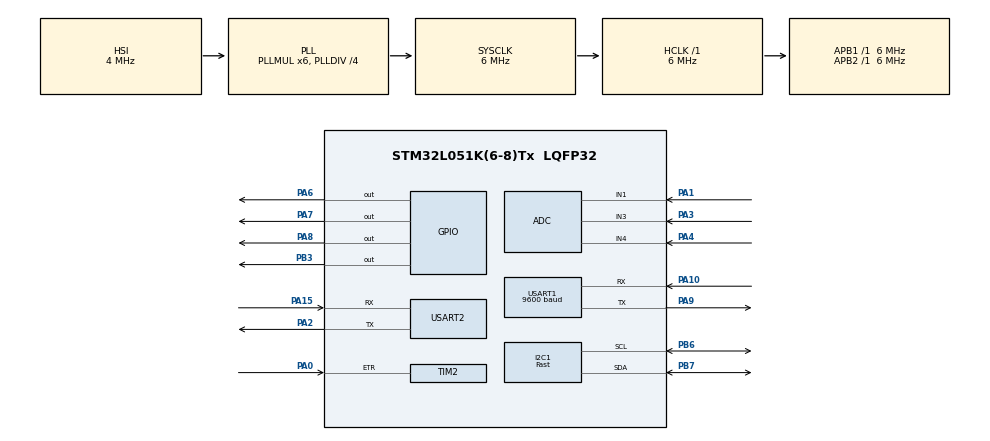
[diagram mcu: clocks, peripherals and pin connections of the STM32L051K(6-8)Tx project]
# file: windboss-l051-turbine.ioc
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ADC.ClockPrescaler=ADC_CLOCK_ASYNC_DIV1
ADC.ContinuousConvMode=ENABLE
ADC.DMAContinuousRequests=ENABLE
Dma.ADC.0.Direction=DMA_PERIPH_TO_MEMORY
Dma.ADC.0.Instance=DMA1_Channel1
Dma.ADC.0.MemDataAlignment=DMA_MDATAALIGN_HALFWORD
Dma.ADC.0.MemInc=DMA_MINC_ENABLE
Dma.ADC.0.Mode=DMA_NORMAL
Dma.ADC.0.PeriphDataAlignment=DMA_PDATAALIGN_HALFWORD
Dma.ADC.0.PeriphInc=DMA_PINC_DISABLE
Dma.ADC.0.Priority=DMA_PRIORITY_VERY_HIGH
Dma.Request0=ADC
I2C1.I2C_Speed_Mode=I2C_Fast
I2C1.Timing=0x00000107
Mcu.Family=STM32L0
Mcu.Name=STM32L051K(6-8)Tx
Mcu.Package=LQFP32
NVIC.DMA1_Channel1_IRQn=true\:0\:0\:false\:false\:true\:false\:true\:true
NVIC.USART1_IRQn=true\:0\:0\:false\:false\:true\:true\:true\:true
PA0.GPIO_Speed=GPIO_SPEED_FREQ_VERY_HIGH
PA0.Signal=S_TIM2_ETR
PA1.Mode=IN1
PA1.Signal=ADC_IN1
PA10.GPIO_PuPd=GPIO_PULLUP
PA10.Mode=Asynchronous
PA10.Signal=USART1_RX
PA13.Mode=Serial_Wire
PA13.Signal=SYS_SWDIO
PA14.Mode=Serial_Wire
PA14.Signal=SYS_SWCLK
PA15.GPIO_PuPd=GPIO_PULLUP
PA15.Mode=Asynchronous
PA15.Signal=USART2_RX
PA2.GPIO_PuPd=GPIO_PULLUP
PA2.Mode=Asynchronous
PA2.Signal=USART2_TX
PA3.Mode=IN3
PA3.Signal=ADC_IN3
PA4.Mode=IN4
PA4.Signal=ADC_IN4
PA5.Signal=S_TIM2_CH1
PA6.GPIO_Speed=GPIO_SPEED_FREQ_HIGH
PA6.Signal=GPIO_Output
PA7.GPIO_Speed=GPIO_SPEED_FREQ_HIGH
PA7.Signal=GPIO_Output
PA8.GPIO_Speed=GPIO_SPEED_FREQ_HIGH
PA8.Signal=GPIO_Output
PA9.GPIO_PuPd=GPIO_PULLUP
PA9.Mode=Asynchronous
PA9.Signal=USART1_TX
PB3.GPIO_PuPd=GPIO_PULLUP
PB3.GPIO_Speed=GPIO_SPEED_FREQ_VERY_HIGH
PB3.PinState=GPIO_PIN_SET
PB3.Signal=GPIO_Output
PB6.GPIO_FM6=I2C_FASTMODEPLUS_PB6
PB6.GPIO_Pu=GPIO_NOPULL
PB6.Mode=I2C
PB6.Signal=I2C1_SCL
PB7.GPIO_FM7=I2C_FASTMODEPLUS_PB7
PB7.GPIO_Pu=GPIO_NOPULL
PB7.Mode=I2C
PB7.Signal=I2C1_SDA
ProjectManager.HeapSize=0x200
ProjectManager.StackSize=0x400
ProjectManager.TargetToolchain=STM32CubeIDE
RCC.ADCFreq_Value=4000000
RCC.AHBFreq_Value=6000000
RCC.APB1Freq_Value=6000000
RCC.APB1TimFreq_Value=6000000
RCC.APB2Freq_Value=6000000
RCC.APB2TimFreq_Value=6000000
RCC.HCLKFreq_Value=6000000
RCC.HSI16_VALUE=16000000
RCC.HSIRCDiv=4
RCC.HSI_VALUE=4000000
RCC.LSE_VALUE=32768
RCC.LptimClockSelection=RCC_LPTIM1CLKSOURCE_HSI
RCC.MSI_VALUE=2097000
RCC.PLLDIV=RCC_PLLDIV_4
RCC.PLLMUL=RCC_PLLMUL_6
RCC.SYSCLKFreq_VALUE=6000000
RCC.SYSCLKSource=RCC_SYSCLKSOURCE_PLLCLK
RCC.Usart1ClockSelection=RCC_USART1CLKSOURCE_SYSCLK
RCC.Usart2ClockSelection=RCC_USART2CLKSOURCE_SYSCLK
RCC.VCOOutputFreq_Value=24000000
SH.S_TIM2_CH1.0=TIM2_CH1
SH.S_TIM2_ETR.0=TIM2_ETR,ClockSourceETR_Mode2
USART1.BaudRate=9600
USART1.DMADisableonRxErrorParam=ADVFEATURE_DMA_DISABLEONRXERROR
USART1.OneBitSampling=UART_ONE_BIT_SAMPLE_DISABLE
USART1.OverSampling=UART_OVERSAMPLING_16
USART1.OverrunDisableParam=ADVFEATURE_OVERRUN_DISABLE
USART1.VirtualMode-Asynchronous=VM_ASYNC
USART2.DMADisableonRxErrorParam=ADVFEATURE_DMA_DISABLEONRXERROR
USART2.OverrunDisableParam=ADVFEATURE_OVERRUN_DISABLE
USART2.VirtualMode-Asynchronous=VM_ASYNC
board=custom

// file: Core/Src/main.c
/* USER CODE BEGIN Header */
/**
  ******************************************************************************
  * @file           : main.c
  * @brief          : Main program body
  ******************************************************************************
  * @attention
  *
  * Copyright (c) 2024 STMicroelectronics.
  * All rights reserved.
  *
  * This software is licensed under terms that can be found in the LICENSE file
  * in the root directory of this software component.
  * If no LICENSE file comes with this software, it is provided AS-IS.
  *
  ******************************************************************************
  */
/* USER CODE END Header */
#include "main.h"

/* USER CODE BEGIN Includes */
#include "tasks.h"
/* USER CODE END Includes */

ADC_HandleTypeDef hadc;
DMA_HandleTypeDef hdma_adc;

I2C_HandleTypeDef hi2c1;

TIM_HandleTypeDef htim2;

UART_HandleTypeDef huart1;
UART_HandleTypeDef huart2;

void SystemClock_Config(void);
static void MX_GPIO_Init(void);
static void MX_DMA_Init(void);
static void MX_ADC_Init(void);
static void MX_I2C1_Init(void);
static void MX_USART1_UART_Init(void);
static void MX_USART2_UART_Init(void);
static void MX_TIM2_Init(void);

int main(void)
{

  /* MCU Configuration--------------------------------------------------------*/

  /* Reset of all peripherals, Initializes the Flash interface and the Systick. */
  HAL_Init();

  /* Configure the system clock */
  SystemClock_Config();

  /* Initialize all configured peripherals */
  MX_GPIO_Init();
  MX_DMA_Init();
  MX_ADC_Init();
  MX_I2C1_Init();
  MX_USART1_UART_Init();
  MX_USART2_UART_Init();
  MX_TIM2_Init();
  /* USER CODE BEGIN 2 */
  tasksInit();
  /* USER CODE END 2 */

  /* Infinite loop */
  while (1)
  {

    /* USER CODE BEGIN 3 */
	tasksLoop();
  }
  /* USER CODE END 3 */
}

void SystemClock_Config(void)
{
  RCC_OscInitTypeDef RCC_OscInitStruct = {0};
  RCC_ClkInitTypeDef RCC_ClkInitStruct = {0};
  RCC_PeriphCLKInitTypeDef PeriphClkInit = {0};

  /** Configure the main internal regulator output voltage
  */
  __HAL_PWR_VOLTAGESCALING_CONFIG(PWR_REGULATOR_VOLTAGE_SCALE1);

  /** Initializes the RCC Oscillators according to the specified parameters
  * in the RCC_OscInitTypeDef structure.
  */
  RCC_OscInitStruct.OscillatorType = RCC_OSCILLATORTYPE_HSI;
  RCC_OscInitStruct.HSIState = RCC_HSI_DIV4;
  RCC_OscInitStruct.HSICalibrationValue = RCC_HSICALIBRATION_DEFAULT;
  RCC_OscInitStruct.PLL.PLLState = RCC_PLL_ON;
  RCC_OscInitStruct.PLL.PLLSource = RCC_PLLSOURCE_HSI;
  RCC_OscInitStruct.PLL.PLLMUL = RCC_PLLMUL_6;
  RCC_OscInitStruct.PLL.PLLDIV = RCC_PLLDIV_4;
  if (HAL_RCC_OscConfig(&RCC_OscInitStruct) != HAL_OK)
  {
    Error_Handler();
  }

  /** Initializes the CPU, AHB and APB buses clocks
  */
  RCC_ClkInitStruct.ClockType = RCC_CLOCKTYPE_HCLK|RCC_CLOCKTYPE_SYSCLK
                              |RCC_CLOCKTYPE_PCLK1|RCC_CLOCKTYPE_PCLK2;
  RCC_ClkInitStruct.SYSCLKSource = RCC_SYSCLKSOURCE_PLLCLK;
  RCC_ClkInitStruct.AHBCLKDivider = RCC_SYSCLK_DIV1;
  RCC_ClkInitStruct.APB1CLKDivider = RCC_HCLK_DIV1;
  RCC_ClkInitStruct.APB2CLKDivider = RCC_HCLK_DIV1;

  if (HAL_RCC_ClockConfig(&RCC_ClkInitStruct, FLASH_LATENCY_0) != HAL_OK)
  {
    Error_Handler();
  }
  PeriphClkInit.PeriphClockSelection = RCC_PERIPHCLK_USART1|RCC_PERIPHCLK_USART2
                              |RCC_PERIPHCLK_I2C1;
  PeriphClkInit.Usart1ClockSelection = RCC_USART1CLKSOURCE_SYSCLK;
  PeriphClkInit.Usart2ClockSelection = RCC_USART2CLKSOURCE_SYSCLK;
  PeriphClkInit.I2c1ClockSelection = RCC_I2C1CLKSOURCE_PCLK1;
  if (HAL_RCCEx_PeriphCLKConfig(&PeriphClkInit) != HAL_OK)
  {
    Error_Handler();
  }
}

static void MX_ADC_Init(void)
{

  ADC_ChannelConfTypeDef sConfig = {0};

  /** Configure the global features of the ADC (Clock, Resolution, Data Alignment and number of conversion)
  */
  hadc.Instance = ADC1;
  hadc.Init.OversamplingMode = DISABLE;
  hadc.Init.ClockPrescaler = ADC_CLOCK_ASYNC_DIV1;
  hadc.Init.Resolution = ADC_RESOLUTION_12B;
  hadc.Init.SamplingTime = ADC_SAMPLETIME_1CYCLE_5;
  hadc.Init.ScanConvMode = ADC_SCAN_DIRECTION_FORWARD;
  hadc.Init.DataAlign = ADC_DATAALIGN_RIGHT;
  hadc.Init.ContinuousConvMode = ENABLE;
  hadc.Init.DiscontinuousConvMode = DISABLE;
  hadc.Init.ExternalTrigConvEdge = ADC_EXTERNALTRIGCONVEDGE_NONE;
  hadc.Init.ExternalTrigConv = ADC_SOFTWARE_START;
  hadc.Init.DMAContinuousRequests = ENABLE;
  hadc.Init.EOCSelection = ADC_EOC_SINGLE_CONV;
  hadc.Init.Overrun = ADC_OVR_DATA_PRESERVED;
  hadc.Init.LowPowerAutoWait = DISABLE;
  hadc.Init.LowPowerFrequencyMode = DISABLE;
  hadc.Init.LowPowerAutoPowerOff = DISABLE;
  if (HAL_ADC_Init(&hadc) != HAL_OK)
  {
    Error_Handler();
  }

  /** Configure for the selected ADC regular channel to be converted.
  */
  sConfig.Channel = ADC_CHANNEL_1;
  sConfig.Rank = ADC_RANK_CHANNEL_NUMBER;
  if (HAL_ADC_ConfigChannel(&hadc, &sConfig) != HAL_OK)
  {
    Error_Handler();
  }

  /** Configure for the selected ADC regular channel to be converted.
  */
  sConfig.Channel = ADC_CHANNEL_3;
  if (HAL_ADC_ConfigChannel(&hadc, &sConfig) != HAL_OK)
  {
    Error_Handler();
  }

  /** Configure for the selected ADC regular channel to be converted.
  */
  sConfig.Channel = ADC_CHANNEL_4;
  if (HAL_ADC_ConfigChannel(&hadc, &sConfig) != HAL_OK)
  {
    Error_Handler();
  }

}

static void MX_I2C1_Init(void)
{

  hi2c1.Instance = I2C1;
  hi2c1.Init.Timing = 0x00000107;
  hi2c1.Init.OwnAddress1 = 0;
  hi2c1.Init.AddressingMode = I2C_ADDRESSINGMODE_7BIT;
  hi2c1.Init.DualAddressMode = I2C_DUALADDRESS_DISABLE;
  hi2c1.Init.OwnAddress2 = 0;
  hi2c1.Init.OwnAddress2Masks = I2C_OA2_NOMASK;
  hi2c1.Init.GeneralCallMode = I2C_GENERALCALL_DISABLE;
  hi2c1.Init.NoStretchMode = I2C_NOSTRETCH_DISABLE;
  if (HAL_I2C_Init(&hi2c1) != HAL_OK)
  {
    Error_Handler();
  }

  /** Configure Analogue filter
  */
  if (HAL_I2CEx_ConfigAnalogFilter(&hi2c1, I2C_ANALOGFILTER_ENABLE) != HAL_OK)
  {
    Error_Handler();
  }

  /** Configure Digital filter
  */
  if (HAL_I2CEx_ConfigDigitalFilter(&hi2c1, 0) != HAL_OK)
  {
    Error_Handler();
  }

}

static void MX_TIM2_Init(void)
{

  TIM_ClockConfigTypeDef sClockSourceConfig = {0};
  TIM_MasterConfigTypeDef sMasterConfig = {0};

  htim2.Instance = TIM2;
  htim2.Init.Prescaler = 0;
  htim2.Init.CounterMode = TIM_COUNTERMODE_UP;
  htim2.Init.Period = 65535;
  htim2.Init.ClockDivision = TIM_CLOCKDIVISION_DIV1;
  htim2.Init.AutoReloadPreload = TIM_AUTORELOAD_PRELOAD_DISABLE;
  if (HAL_TIM_Base_Init(&htim2) != HAL_OK)
  {
    Error_Handler();
  }
  sClockSourceConfig.ClockSource = TIM_CLOCKSOURCE_ETRMODE2;
  sClockSourceConfig.ClockPolarity = TIM_CLOCKPOLARITY_NONINVERTED;
  sClockSourceConfig.ClockPrescaler = TIM_CLOCKPRESCALER_DIV1;
  sClockSourceConfig.ClockFilter = 0;
  if (HAL_TIM_ConfigClockSource(&htim2, &sClockSourceConfig) != HAL_OK)
  {
    Error_Handler();
  }
  sMasterConfig.MasterOutputTrigger = TIM_TRGO_RESET;
  sMasterConfig.MasterSlaveMode = TIM_MASTERSLAVEMODE_DISABLE;
  if (HAL_TIMEx_MasterConfigSynchronization(&htim2, &sMasterConfig) != HAL_OK)
  {
    Error_Handler();
  }

}

static void MX_USART1_UART_Init(void)
{

  huart1.Instance = USART1;
  huart1.Init.BaudRate = 9600;
  huart1.Init.WordLength = UART_WORDLENGTH_8B;
  huart1.Init.StopBits = UART_STOPBITS_1;
  huart1.Init.Parity = UART_PARITY_NONE;
  huart1.Init.Mode = UART_MODE_TX_RX;
  huart1.Init.HwFlowCtl = UART_HWCONTROL_NONE;
  huart1.Init.OverSampling = UART_OVERSAMPLING_16;
  huart1.Init.OneBitSampling = UART_ONE_BIT_SAMPLE_DISABLE;
  huart1.AdvancedInit.AdvFeatureInit = UART_ADVFEATURE_RXOVERRUNDISABLE_INIT|UART_ADVFEATURE_DMADISABLEONERROR_INIT;
  huart1.AdvancedInit.OverrunDisable = UART_ADVFEATURE_OVERRUN_DISABLE;
  huart1.AdvancedInit.DMADisableonRxError = UART_ADVFEATURE_DMA_DISABLEONRXERROR;
  if (HAL_UART_Init(&huart1) != HAL_OK)
  {
    Error_Handler();
  }

}

static void MX_USART2_UART_Init(void)
{

  huart2.Instance = USART2;
  huart2.Init.BaudRate = 115200;
  huart2.Init.WordLength = UART_WORDLENGTH_8B;
  huart2.Init.StopBits = UART_STOPBITS_1;
  huart2.Init.Parity = UART_PARITY_NONE;
  huart2.Init.Mode = UART_MODE_TX_RX;
  huart2.Init.HwFlowCtl = UART_HWCONTROL_NONE;
  huart2.Init.OverSampling = UART_OVERSAMPLING_16;
  huart2.Init.OneBitSampling = UART_ONE_BIT_SAMPLE_DISABLE;
  huart2.AdvancedInit.AdvFeatureInit = UART_ADVFEATURE_RXOVERRUNDISABLE_INIT|UART_ADVFEATURE_DMADISABLEONERROR_INIT;
  huart2.AdvancedInit.OverrunDisable = UART_ADVFEATURE_OVERRUN_DISABLE;
  huart2.AdvancedInit.DMADisableonRxError = UART_ADVFEATURE_DMA_DISABLEONRXERROR;
  if (HAL_UART_Init(&huart2) != HAL_OK)
  {
    Error_Handler();
  }

}

static void MX_DMA_Init(void)
{

  /* DMA controller clock enable */
  __HAL_RCC_DMA1_CLK_ENABLE();

  /* DMA interrupt init */
  /* DMA1_Channel1_IRQn interrupt configuration */
  HAL_NVIC_SetPriority(DMA1_Channel1_IRQn, 0, 0);
  HAL_NVIC_EnableIRQ(DMA1_Channel1_IRQn);

}

static void MX_GPIO_Init(void)
{
  GPIO_InitTypeDef GPIO_InitStruct = {0};

  /* GPIO Ports Clock Enable */
  __HAL_RCC_GPIOA_CLK_ENABLE();
  __HAL_RCC_GPIOB_CLK_ENABLE();

  /*Configure GPIO pin Output Level */
  HAL_GPIO_WritePin(GPIOA, GPIO_PIN_6|GPIO_PIN_7|GPIO_PIN_8, GPIO_PIN_RESET);

  /*Configure GPIO pin Output Level */
  HAL_GPIO_WritePin(GPIOB, GPIO_PIN_3, GPIO_PIN_SET);

  /*Configure GPIO pins : PA6 PA7 PA8 */
  GPIO_InitStruct.Pin = GPIO_PIN_6|GPIO_PIN_7|GPIO_PIN_8;
  GPIO_InitStruct.Mode = GPIO_MODE_OUTPUT_PP;
  GPIO_InitStruct.Pull = GPIO_NOPULL;
  GPIO_InitStruct.Speed = GPIO_SPEED_FREQ_HIGH;
  HAL_GPIO_Init(GPIOA, &GPIO_InitStruct);

  /*Configure GPIO pin : PB3 */
  GPIO_InitStruct.Pin = GPIO_PIN_3;
  GPIO_InitStruct.Mode = GPIO_MODE_OUTPUT_PP;
  GPIO_InitStruct.Pull = GPIO_PULLUP;
  GPIO_InitStruct.Speed = GPIO_SPEED_FREQ_VERY_HIGH;
  HAL_GPIO_Init(GPIOB, &GPIO_InitStruct);

}

void Error_Handler(void)
{
  __disable_irq();
  while (1)
  {
  }
}
